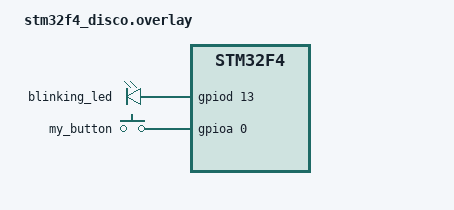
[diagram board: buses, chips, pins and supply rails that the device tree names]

/ {
    leds {
        status = "okay";
        compatible = "gpio-leds"; 
        blinking_led: blinking_led { //yorum
            status = "okay";
            gpios = <&gpiod 13 GPIO_ACTIVE_HIGH>;  // GPIO_ACTIVE_HIGH (or GPIO_ACTIVE_LOW): Specifies the active logic level of a GPIO pin.
        };
    };

    buttons {
        status = "okay";
        compatible = "gpio-keys";
        my_button: my_button {
            status = "okay";
            gpios = <&gpioa 0 GPIO_ACTIVE_HIGH>;
        };
    };
};
